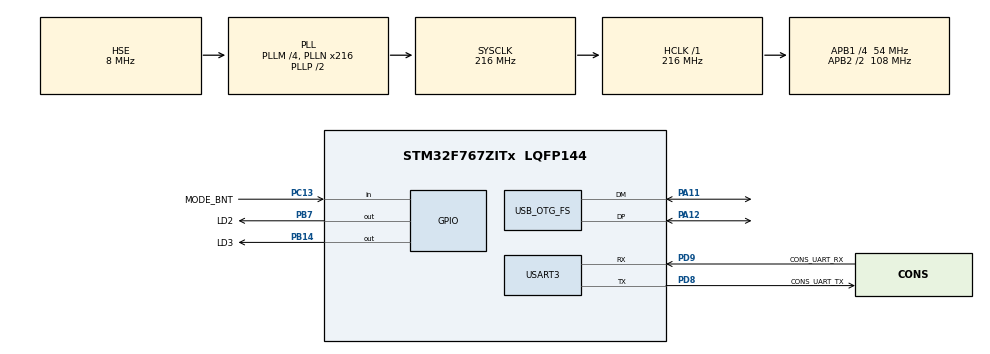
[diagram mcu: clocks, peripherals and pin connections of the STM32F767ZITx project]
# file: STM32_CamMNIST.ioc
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CORTEX_M7.CPU_DCache=Enabled
CORTEX_M7.CPU_ICache=Enabled
CORTEX_M7.MPU_Control=__NULL
EdgeImpulse.ml_mnist.1.0.1.MachineLearningCcmlIimnistJjCore=true
Mcu.Family=STM32F7
Mcu.Name=STM32F767ZITx
Mcu.Package=LQFP144
NVIC.OTG_FS_IRQn=true\:0\:0\:false\:false\:true\:false\:true\:true
NVIC.PriorityGroup=NVIC_PRIORITYGROUP_4
NVIC.TIM8_TRG_COM_TIM14_IRQn=true\:0\:0\:false\:false\:true\:true\:true\:true
NVIC.USART3_IRQn=true\:0\:0\:false\:false\:true\:true\:true\:true
PA11.Mode=Device_Only
PA11.Signal=USB_OTG_FS_DM
PA12.Mode=Device_Only
PA12.Signal=USB_OTG_FS_DP
PA13.Mode=Trace_Asynchronous_SW
PA13.Signal=SYS_JTMS-SWDIO
PA14.Mode=Trace_Asynchronous_SW
PA14.Signal=SYS_JTCK-SWCLK
PB14.GPIO_Label=LD3
PB14.Signal=GPIO_Output
PB3.Mode=Trace_Asynchronous_SW
PB3.Signal=SYS_JTDO-SWO
PB7.GPIO_Label=LD2
PB7.Signal=GPIO_Output
PC13.GPIO_Label=MODE_BNT
PC13.GPIO_PuPd=GPIO_PULLDOWN
PC13.Signal=GPIO_Input
PD8.GPIO_Label=CONS_UART_TX
PD8.Mode=Asynchronous
PD8.Signal=USART3_TX
PD9.GPIO_Label=CONS_UART_RX
PD9.Mode=Asynchronous
PD9.Signal=USART3_RX
PH0/OSC_IN.Mode=HSE-External-Clock-Source
PH0/OSC_IN.Signal=RCC_OSC_IN
PH1/OSC_OUT.Mode=HSE-External-Clock-Source
PH1/OSC_OUT.Signal=RCC_OSC_OUT
ProjectManager.HeapSize=0x600
ProjectManager.StackSize=0x400
ProjectManager.TargetToolchain=STM32CubeIDE
RCC.AHBFreq_Value=216000000
RCC.APB1CLKDivider=RCC_HCLK_DIV4
RCC.APB1Freq_Value=54000000
RCC.APB1TimFreq_Value=108000000
RCC.APB2CLKDivider=RCC_HCLK_DIV2
RCC.APB2Freq_Value=108000000
RCC.APB2TimFreq_Value=216000000
RCC.CortexFreq_Value=216000000
RCC.HCLKFreq_Value=216000000
RCC.HSE_VALUE=8000000
RCC.HSI_VALUE=16000000
RCC.LSE_VALUE=32768
RCC.PLLM=4
RCC.PLLN=216
RCC.PLLQ=9
RCC.SYSCLKFreq_VALUE=216000000
RCC.SYSCLKSource=RCC_SYSCLKSOURCE_PLLCLK
RCC.USBFreq_Value=48000000
RCC.VCOOutputFreq_Value=432000000
TIM14.Prescaler=128
USART3.VirtualMode-Asynchronous=VM_ASYNC
USB_DEVICE.CLASS_NAME_FS=CDC
USB_DEVICE.VirtualMode-CDC_FS=Cdc
USB_DEVICE.VirtualModeFS=Cdc_FS
USB_OTG_FS.VirtualMode=Device_Only
VP_CRC_VS_CRC.Mode=CRC_Activate
VP_EdgeImpulse.ml_mnist_VS_mlIimnistJjMachineLearning_1.0.1_1.0.1.Mode=mlIimnistJjMachineLearning
VP_TIM14_VS_ClockSourceINT.Mode=Enable_Timer
VP_USB_DEVICE_VS_USB_DEVICE_CDC_FS.Mode=CDC_FS
board=custom

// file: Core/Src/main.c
/* USER CODE BEGIN Header */
/**
  ******************************************************************************
  * @file           : main.c
  * @brief          : Main program body
  ******************************************************************************
  * @attention
  *
  * Copyright (c) 2023 STMicroelectronics.
  * All rights reserved.
  *
  * This software is licensed under terms that can be found in the LICENSE file
  * in the root directory of this software component.
  * If no LICENSE file comes with this software, it is provided AS-IS.
  *
  ******************************************************************************
  */
/* USER CODE END Header */
#include "main.h"
#include "crc.h"
#include "tim.h"
#include "usart.h"
#include "usb_device.h"
#include "gpio.h"

/* USER CODE BEGIN Includes */
#include "usbd_cdc_if.h"
#include "main_logic.h"
/* USER CODE END Includes */

void SystemClock_Config(void);

int main(void)
{
/* Enable the CPU Cache */

  /* Enable I-Cache---------------------------------------------------------*/
  SCB_EnableICache();

  /* Enable D-Cache---------------------------------------------------------*/
  SCB_EnableDCache();

  /* MCU Configuration--------------------------------------------------------*/

  /* Reset of all peripherals, Initializes the Flash interface and the Systick. */
  HAL_Init();

  /* Configure the system clock */
  SystemClock_Config();

  /* Initialize all configured peripherals */
  MX_GPIO_Init();
  MX_USB_DEVICE_Init();
  MX_USART3_UART_Init();
  MX_CRC_Init();
  MX_TIM14_Init();
  /* USER CODE BEGIN 2 */
  init();
  /* USER CODE END 2 */

  /* Infinite loop */
  while (1)
  {

    /* USER CODE BEGIN 3 */
	run();
  }
  /* USER CODE END 3 */
}

void SystemClock_Config(void)
{
  RCC_OscInitTypeDef RCC_OscInitStruct = {0};
  RCC_ClkInitTypeDef RCC_ClkInitStruct = {0};

  /** Configure the main internal regulator output voltage
  */
  __HAL_RCC_PWR_CLK_ENABLE();
  __HAL_PWR_VOLTAGESCALING_CONFIG(PWR_REGULATOR_VOLTAGE_SCALE1);

  /** Initializes the RCC Oscillators according to the specified parameters
  * in the RCC_OscInitTypeDef structure.
  */
  RCC_OscInitStruct.OscillatorType = RCC_OSCILLATORTYPE_HSE;
  RCC_OscInitStruct.HSEState = RCC_HSE_BYPASS;
  RCC_OscInitStruct.PLL.PLLState = RCC_PLL_ON;
  RCC_OscInitStruct.PLL.PLLSource = RCC_PLLSOURCE_HSE;
  RCC_OscInitStruct.PLL.PLLM = 4;
  RCC_OscInitStruct.PLL.PLLN = 216;
  RCC_OscInitStruct.PLL.PLLP = RCC_PLLP_DIV2;
  RCC_OscInitStruct.PLL.PLLQ = 9;
  RCC_OscInitStruct.PLL.PLLR = 2;
  if (HAL_RCC_OscConfig(&RCC_OscInitStruct) != HAL_OK)
  {
    Error_Handler();
  }

  /** Activate the Over-Drive mode
  */
  if (HAL_PWREx_EnableOverDrive() != HAL_OK)
  {
    Error_Handler();
  }

  /** Initializes the CPU, AHB and APB buses clocks
  */
  RCC_ClkInitStruct.ClockType = RCC_CLOCKTYPE_HCLK|RCC_CLOCKTYPE_SYSCLK
                              |RCC_CLOCKTYPE_PCLK1|RCC_CLOCKTYPE_PCLK2;
  RCC_ClkInitStruct.SYSCLKSource = RCC_SYSCLKSOURCE_PLLCLK;
  RCC_ClkInitStruct.AHBCLKDivider = RCC_SYSCLK_DIV1;
  RCC_ClkInitStruct.APB1CLKDivider = RCC_HCLK_DIV4;
  RCC_ClkInitStruct.APB2CLKDivider = RCC_HCLK_DIV2;

  if (HAL_RCC_ClockConfig(&RCC_ClkInitStruct, FLASH_LATENCY_7) != HAL_OK)
  {
    Error_Handler();
  }
}

void Error_Handler(void)
{
  __disable_irq();
  while (1)
  {
  }
}
